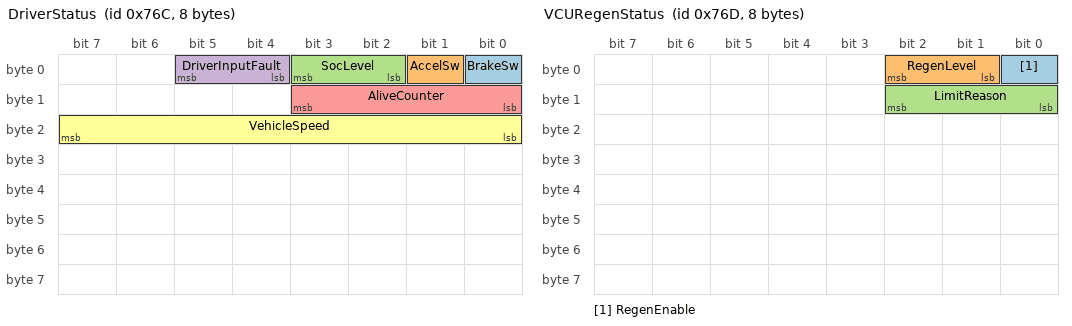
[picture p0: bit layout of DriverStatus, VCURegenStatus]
VERSION ""

NS_ :

BS_:

BU_: TestClient ECU4 ECU3 ECU1 ECU2

 BO_ 1900 DriverStatus: 8 TestClient
 SG_ BrakeSw : 0|1@1+ (1,0) [0|1] "" TestClient
 SG_ AccelSw : 1|1@1+ (1,0) [0|1] "" TestClient
 SG_ SocLevel : 2|2@1+ (1,0) [0|3] "" TestClient
 SG_ DriverInputFault : 4|2@1+ (1,0) [0|3] "" TestClient
 SG_ AliveCounter : 8|4@1+ (1,0) [0|15] "" TestClient
 SG_ VehicleSpeed : 16|8@1+ (1,0) [0|255] "km/h" TestClient

BO_ 1901 VCURegenStatus: 8 TestClient
 SG_ RegenEnable : 0|1@1+ (1,0) [0|1] "" TestClient
 SG_ RegenLevel : 1|2@1+ (1,0) [0|3] "" TestClient
 SG_ LimitReason : 8|3@1+ (1,0) [0|7] "" TestClient

 VAL_ 1900 BrakeSw 0 "OFF" 1 "ON";
VAL_ 1900 AccelSw 0 "OFF" 1 "ON";

0 "LOW"
1 "MID"
2 "HIGH"
3 "FULL";

0 "NONE"
1 "PEDAL_CONFLICT"
2 "INPUT_READ_FAIL"
3 "RESERVED";

0 "DISABLE"
1 "ENABLE";

0 "NONE"
1 "LOW"
2 "MID"
3 "HIGH";

0 "NONE"
1 "LOW_SPEED"
2 "SOC_FULL"
3 "FAULT"
4 "TIMEOUT";

BA_ "GenMsgCycleTime" BO_ 1900 10;
BA_ "GenMsgCycleTime" BO_ 1901 10;

BA_ "GenMsgSendType" BO_ 1900 0;
BA_ "GenMsgSendType" BO_ 1901 0;

BA_ "GenMsgDelayTime" BO_ 1900 0;
BA_ "GenMsgDelayTime" BO_ 1901 0;

BO_ 1799 GST_Msg_TP2: 8 TestClient
 SG_ GST_Msg_TP2_Sig1 : 0|64@1+ (1,0) [0|0] ""  ECU1

BO_ 1798 GST_Msg_TP1: 8 TestClient
 SG_ GST_Msg_TP1_Sig1 : 0|64@1+ (1,0) [0|0] ""  ECU1

BO_ 1797 ECU1_GST_Msg_TP: 8 ECU1
 SG_ ECU1_GST_TP_Sig1 : 7|64@0+ (1,0) [0|0] ""  TestClient

BO_ 85 ECU1_Msg_GW1: 8 ECU1
 SG_ ECU1_Msg_GW1_Sig2 : 15|8@0+ (1,0) [0|0] "" Vector__XXX
 SG_ ECU1_Msg_GW1_Sig1 : 7|8@0+ (1,0) [0|0] "" Vector__XXX

BO_ 1795 GST_Msg_TP_Phys: 8 TestClient
 SG_ GST_TP_Phys_Sig1 : 7|64@0+ (1,0) [0|0] ""  ECU1

BO_ 1796 ECU1_Msg_TP2: 8 ECU1
 SG_ ECU1_Msg_TP2_Sig1 : 0|64@1+ (1,0) [0|0] ""  TestClient

BO_ 769 ECU2_Msg_PIF1: 8 ECU2
 SG_ ECU2_Msg_PIF1_Sig2 : 31|8@0+ (1,0) [0|0] ""  ECU1
 SG_ ECU2_Msg_PIF1_Sig1 : 23|8@0+ (1,0) [0|0] ""  ECU1

BO_ 259 ECU2_Msg_POE1: 8 ECU2
 SG_ ECU2_Msg_POE1_Sig1 : 31|8@0+ (1,0) [0|0] ""  ECU1
 SG_ ECU2_Msg_POE1_Sig2 : 23|8@0+ (1,0) [0|0] ""  ECU1

BO_ 512 ECU1_Msg_IF1: 8 ECU1
 SG_ ECU1_Msg_IF1_Sig2 : 15|8@0+ (1,0) [0|0] ""  TestClient
 SG_ ECU1_Msg_IF1_Sig1 : 7|8@0+ (1,0) [0|0] ""  TestClient

BO_ 0 ECU2_Msg_OE2: 8 ECU2
 SG_ ECU2_Msg_OE2_Sig1 : 7|64@0+ (1,0) [0|0] ""  ECU3

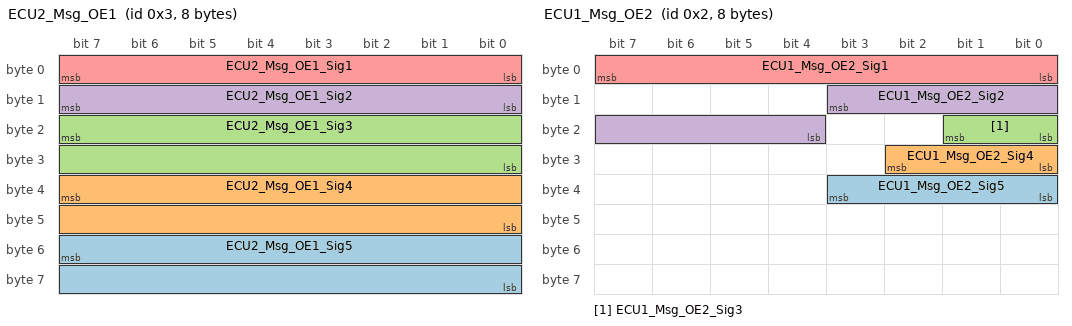
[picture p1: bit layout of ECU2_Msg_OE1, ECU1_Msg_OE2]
BO_ 3 ECU2_Msg_OE1: 8 ECU2
 SG_ ECU2_Msg_OE1_Sig5 : 55|16@0+ (1,0) [0|0] "" Vector__XXX
 SG_ ECU2_Msg_OE1_Sig4 : 39|16@0+ (1,0) [0|0] "" Vector__XXX
 SG_ ECU2_Msg_OE1_Sig3 : 23|16@0+ (1,0) [0|0] "" Vector__XXX
 SG_ ECU2_Msg_OE1_Sig2 : 15|8@0+ (1,0) [0|0] ""  ECU1
 SG_ ECU2_Msg_OE1_Sig1 : 7|8@0+ (1,0) [0|0] ""  ECU1

BO_ 1283 ECU2_Msg_P1: 2 ECU2
 SG_ ECU2_Msg_P1_Sig2 : 15|8@0+ (1,0) [0|0] ""  ECU1
 SG_ ECU2_Msg_P1_Sig1 : 7|8@0+ (1,0) [0|0] ""  ECU1

BO_ 256 ECU1_Msg_POE3: 8 ECU1
 SG_ ECU1_Msg_POE3_Sig2 : 15|8@0+ (1,0) [0|0] ""  ECU2
 SG_ ECU1_Msg_POE3_Sig1 : 7|8@0+ (1,0) [0|255] ""  ECU2

BO_ 2015 GST_Msg_TP_Func: 8 TestClient
 SG_ GST_TP_Func_Sig1 : 7|64@0+ (1,0) [0|0] ""  ECU1

BO_ 1793 ECU1_Msg_TP1: 8 ECU1
 SG_ ECU1_Msg_TP1_Sig1 : 0|64@1+ (1,0) [0|0] ""  TestClient

BO_ 1538 ECU1_Msg_P4: 8 ECU1
 SG_ ECU1_Msg_P4_Sig2 : 15|8@0+ (1,0) [0|0] ""  ECU2
 SG_ ECU1_Msg_P4_Sig1 : 7|8@0+ (1,0) [0|0] ""  ECU2

BO_ 1537 ECU1_Msg_P3: 8 ECU1
 SG_ ECU1_Msg_P3_Sig2 : 15|8@0+ (1,0) [0|0] ""  ECU2
 SG_ ECU1_Msg_P3_Sig1 : 7|8@0+ (1,0) [0|0] ""  ECU2

BO_ 768 ECU1_Msg_PIF1: 8 ECU1
 SG_ ECU1_Msg_PIF1_Sig2 : 15|8@0+ (1,0) [0|0] ""  TestClient
 SG_ ECU1_Msg_PIF1_Sig1 : 7|8@0+ (1,0) [0|0] ""  TestClient

BO_ 1282 ECU1_Msg_P2: 8 ECU1
 SG_ ECU1_Msg_P2_Sig2 : 15|8@0+ (1,0) [0|0] ""  ECU2
 SG_ ECU1_Msg_P2_Sig1 : 7|8@0+ (1,0) [0|0] ""  ECU2

BO_ 1281 ECU1_Msg_P1: 8 ECU1
 SG_ ECU1_Msg_P1_Sig2 : 15|8@0+ (1,0) [0|0] ""  ECU2
 SG_ ECU1_Msg_P1_Sig1 : 7|8@0+ (1,0) [0|0] ""  ECU2

BO_ 1028 ECU4_Msg_NM: 8 ECU4
 SG_ ECU4_Msg_NM_Sig1 : 7|8@0+ (1,0) [0|0] ""  ECU1,ECU2,ECU3

BO_ 1027 ECU3_Msg_NM: 8 ECU3
 SG_ ECU3_Msg_NM_Sig1 : 7|8@0+ (1,0) [0|0] ""  ECU1,ECU2,ECU4

BO_ 1026 ECU2_Msg_NM: 8 ECU2
 SG_ ECU2_Msg_NM_Sig1 : 7|8@0+ (1,0) [0|0] ""  ECU1,ECU3,ECU4

BO_ 1025 ECU1_Msg_NM: 8 ECU1
 SG_ ECU1_Msg_NM_Sig1 : 7|8@0+ (1,0) [0|0] ""  ECU2,ECU3,ECU4

BO_ 258 ECU1_Msg_POE2: 8 ECU1
 SG_ ECU1_Msg_POE2_Sig2 : 15|8@0+ (1,0) [0|0] ""  ECU2
 SG_ ECU1_Msg_POE2_Sig1 : 7|8@0+ (1,0) [0|0] ""  ECU2

BO_ 257 ECU1_Msg_POE1: 8 ECU1
 SG_ ECU1_Msg_POE1_Sig2 : 15|8@0+ (1,0) [0|0] ""  ECU2
 SG_ ECU1_Msg_POE1_Sig1 : 7|8@0+ (1,0) [0|0] ""  ECU2

BO_ 2 ECU1_Msg_OE2: 8 ECU1
 SG_ ECU1_Msg_OE2_Sig5 : 35|4@0+ (1,0) [0|15] "" Vector__XXX
 SG_ ECU1_Msg_OE2_Sig4 : 26|3@0+ (1,0) [0|7] "" Vector__XXX
 SG_ ECU1_Msg_OE2_Sig3 : 17|2@0+ (1,0) [0|3] "" Vector__XXX
 SG_ ECU1_Msg_OE2_Sig2 : 11|8@0+ (1,0) [0|0] ""  ECU2
 SG_ ECU1_Msg_OE2_Sig1 : 7|8@0+ (1,0) [0|0] ""  ECU2

BO_ 1 ECU1_Msg_OE1: 8 ECU1
 SG_ ECU1_Msg_OE1_Sig2 : 12|8@1+ (1,0) [0|0] ""  ECU2
 SG_ ECU1_Msg_OE1_Sig1 : 7|8@0+ (1,0) [0|0] ""  ECU2

EV_ ET_NwStartupTime: 0 [0|65535] "" 0 1 DUMMY_NODE_VECTOR3 Vector__XXX;

EV_ ET_ECU2_ILControlStop: 0 [0|0] "" 0 2 DUMMY_NODE_VECTOR3 Vector__XXX;

EV_ ET_ECU4_SilentNm: 0 [0|0] "" 0 3 DUMMY_NODE_VECTOR3 Vector__XXX;

EV_ ET_ECU3_SilentNm: 0 [0|0] "" 0 4 DUMMY_NODE_VECTOR3 Vector__XXX;

EV_ ET_ECU2_SilentNm: 0 [0|0] "" 0 5 DUMMY_NODE_VECTOR3 Vector__XXX;

EV_ ET_ECU4_SleepInd: 0 [0|0] "" 0 6 DUMMY_NODE_VECTOR3 Vector__XXX;

EV_ ET_ECU3_SleepInd: 0 [0|0] "" 0 7 DUMMY_NODE_VECTOR3 Vector__XXX;

EV_ ET_ECU2_SleepInd: 0 [0|0] "" 0 8 DUMMY_NODE_VECTOR3 Vector__XXX;

BA_DEF_ SG_  "GwSigLatencyTime" INT 0 65535;
BA_DEF_ SG_  "GwSigMissingSourceType" ENUM  "Undef","OldValue","DefaultValue","InitialValue";
BA_DEF_ SG_  "SignalCategory" HEX 10 15;
BA_DEF_ SG_  "GenSigEnvVarType" ENUM  "int","float","undef";
BA_DEF_ SG_  "GenSigSendType" ENUM  "Cyclic","OnWrite","OnWriteWithRepetition","OnChange","OnChangeWithRepetition","IfActive","IfActiveWithRepetition","NoSigSendType";
BA_DEF_ SG_  "GenSigInactiveValue" INT 0 65535;
BA_DEF_ BO_  "NmMessage" ENUM  "No","Yes";
BA_DEF_ BO_  "GenMsgILSupport" ENUM  "No","Yes";
BA_DEF_ BO_  "GenMsgSendType" ENUM  "Cyclic","not_used","not_used","not_used","not_used","not_used","not_used","not_used","NoMsgSendType";
BA_DEF_ BO_  "GenMsgNrOfRepetition" INT 0 3;
BA_DEF_ BO_  "GenMsgDelayTime" INT 0 20;
BA_DEF_ BO_  "GenMsgCycleTime" INT 0 2000;
BA_DEF_ BO_  "GenMsgCycleTimeFast" INT 0 500;
BA_DEF_ BU_  "NodeLayerModules" STRING ;
BA_DEF_ BU_  "GenNodSleepTime" INT 1375 1650;
BA_DEF_ BU_  "NmNode" ENUM  "No","Yes";
BA_DEF_ BU_  "NmStationAddress" HEX 0 255;
BA_DEF_ BU_  "NmCAN" INT 1 2;
BA_DEF_ BU_  "ILUsed" ENUM  "No","Yes";
BA_DEF_  "VersionWeek" INT 1 53;
BA_DEF_  "VersionMonth" INT 1 12;
BA_DEF_  "VersionDay" INT 1 31;
BA_DEF_  "BusType" STRING ;
BA_DEF_  "GenNWMTalkNM" STRING ;
BA_DEF_  "GenNWMSleepTime" INT 1375 1650;
BA_DEF_  "GenNWMGotoMode_BusSleep" STRING ;
BA_DEF_  "GenNWMGotoMode_Awake" STRING ;
BA_DEF_  "GenNWMApCanWakeUp" STRING ;
BA_DEF_  "GenNWMApCanSleep" STRING ;
BA_DEF_  "GenNWMApCanOn" STRING ;
BA_DEF_  "GenNWMApCanOff" STRING ;
BA_DEF_  "GenNWMApCanNormal" STRING ;
BA_DEF_  "GenNWMApBusSleep" STRING ;
BA_DEF_  "GenEnvVarPrefix" STRING ;
BA_DEF_  "GenEnvVarEndingSnd" STRING ;
BA_DEF_  "GenEnvVarEndingDsp" STRING ;
BA_DEF_  "NmType" STRING ;
BA_DEF_  "NmBaseAddress" HEX 0 2047;
BA_DEF_  "NmMessageCount" INT 0 128;
BA_DEF_  "Manufacturer" STRING ;
BA_DEF_  "Baudrate" INT 50000 500000;
BA_DEF_  "SamplePointMin" INT 55 85;
BA_DEF_  "SamplePointMax" INT 50 85;
BA_DEF_  "SyncJumpWidthMin" INT 1 4;
BA_DEF_  "SyncJumpWidthMax" INT 1 8;
BA_DEF_REL_ BU_SG_REL_  "GenSigTimeoutTime" INT 175 3500;
BA_DEF_DEF_  "GwSigLatencyTime" 40;
BA_DEF_DEF_  "GwSigMissingSourceType" "Undef";
BA_DEF_DEF_  "SignalCategory" 12;
BA_DEF_DEF_  "GenSigEnvVarType" "undef";
BA_DEF_DEF_  "GenSigSendType" "NoSigSendType";
BA_DEF_DEF_  "GenSigInactiveValue" 0;
BA_DEF_DEF_  "NmMessage" "No";
BA_DEF_DEF_  "GenMsgILSupport" "Yes";
BA_DEF_DEF_  "GenMsgSendType" "NoMsgSendType";
BA_DEF_DEF_  "GenMsgNrOfRepetition" 3;
BA_DEF_DEF_  "GenMsgDelayTime" 20;
BA_DEF_DEF_  "GenMsgCycleTime" 200;
BA_DEF_DEF_  "GenMsgCycleTimeFast" 40;
BA_DEF_DEF_  "NodeLayerModules" "oseknm01.dll";
BA_DEF_DEF_  "GenNodSleepTime" 1500;
BA_DEF_DEF_  "NmNode" "Yes";
BA_DEF_DEF_  "NmStationAddress" 0;
BA_DEF_DEF_  "NmCAN" 1;
BA_DEF_DEF_  "ILUsed" "Yes";
BA_DEF_DEF_  "VersionWeek" 1;
BA_DEF_DEF_  "VersionMonth" 1;
BA_DEF_DEF_  "VersionDay" 1;
BA_DEF_DEF_  "BusType" "CAN";
BA_DEF_DEF_  "GenNWMTalkNM" "TalkNM()";
BA_DEF_DEF_  "GenNWMSleepTime" 1500;
BA_DEF_DEF_  "GenNWMGotoMode_BusSleep" "GotoMode_BusSleep()";
BA_DEF_DEF_  "GenNWMGotoMode_Awake" "GotoMode_Awake()";
BA_DEF_DEF_  "GenNWMApCanWakeUp" "ApplCanWakeUp()";
BA_DEF_DEF_  "GenNWMApCanSleep" "ApplNmCanSleep()";
BA_DEF_DEF_  "GenNWMApCanOn" "ApplCanOnline()";
BA_DEF_DEF_  "GenNWMApCanOff" "ApplCanOffline()";
BA_DEF_DEF_  "GenNWMApCanNormal" "ApplNmCanNormal()";
BA_DEF_DEF_  "GenNWMApBusSleep" "ApplNmCanBusSleep()";
BA_DEF_DEF_  "GenEnvVarPrefix" "Env";
BA_DEF_DEF_  "GenEnvVarEndingSnd" "_";
BA_DEF_DEF_  "GenEnvVarEndingDsp" "Dsp_";
BA_DEF_DEF_  "NmType" "Vector";
BA_DEF_DEF_  "NmBaseAddress" 1024;
BA_DEF_DEF_  "NmMessageCount" 128;
BA_DEF_DEF_  "Manufacturer" "HMC";
BA_DEF_DEF_  "Baudrate" 100000;
BA_DEF_DEF_  "SamplePointMin" 75;
BA_DEF_DEF_  "SamplePointMax" 82;
BA_DEF_DEF_  "SyncJumpWidthMin" 2;
BA_DEF_DEF_  "SyncJumpWidthMax" 3;
BA_DEF_DEF_REL_ "GenSigTimeoutTime" 700;
BA_ "Baudrate" 500000;
BA_ "NmStationAddress" BU_ ECU4 4;
BA_ "NmStationAddress" BU_ ECU3 3;
BA_ "NmStationAddress" BU_ ECU1 1;
BA_ "NmStationAddress" BU_ ECU2 2;
BA_ "GenMsgILSupport" BO_ 1799 0;
BA_ "GenMsgNrOfRepetition" BO_ 1799 0;
BA_ "GenMsgDelayTime" BO_ 1799 0;
BA_ "GenMsgCycleTime" BO_ 1799 0;
BA_ "GenMsgCycleTimeFast" BO_ 1799 0;
BA_ "GenMsgILSupport" BO_ 1798 0;
BA_ "GenMsgNrOfRepetition" BO_ 1798 0;
BA_ "GenMsgDelayTime" BO_ 1798 0;
BA_ "GenMsgCycleTime" BO_ 1798 0;
BA_ "GenMsgCycleTimeFast" BO_ 1798 0;
BA_ "GenMsgCycleTimeFast" BO_ 1797 0;
BA_ "GenMsgCycleTime" BO_ 1797 0;
BA_ "GenMsgDelayTime" BO_ 1797 0;
BA_ "GenMsgNrOfRepetition" BO_ 1797 0;
BA_ "GenMsgILSupport" BO_ 1797 0;
BA_ "GenMsgILSupport" BO_ 1795 0;
BA_ "GenMsgNrOfRepetition" BO_ 1795 0;
BA_ "GenMsgDelayTime" BO_ 1795 0;
BA_ "GenMsgCycleTime" BO_ 1795 0;
BA_ "GenMsgCycleTimeFast" BO_ 1795 0;
BA_ "GenMsgILSupport" BO_ 1796 0;
BA_ "GenMsgNrOfRepetition" BO_ 1796 0;
BA_ "GenMsgDelayTime" BO_ 1796 0;
BA_ "GenMsgCycleTime" BO_ 1796 0;
BA_ "GenMsgCycleTimeFast" BO_ 1796 0;
BA_ "GenMsgCycleTimeFast" BO_ 769 200;
BA_ "GenMsgCycleTime" BO_ 769 500;
BA_ "GenMsgSendType" BO_ 769 0;
BA_ "GenMsgCycleTime" BO_ 259 500;
BA_ "GenMsgSendType" BO_ 259 0;
BA_ "GenMsgCycleTimeFast" BO_ 512 200;
BA_ "GenMsgCycleTime" BO_ 512 0;
BA_ "GenMsgCycleTime" BO_ 1283 500;
BA_ "GenMsgSendType" BO_ 1283 0;
BA_ "GenMsgNrOfRepetition" BO_ 1283 0;
BA_ "GenMsgCycleTimeFast" BO_ 1283 0;
BA_ "GenMsgSendType" BO_ 256 0;
BA_ "GenMsgCycleTimeFast" BO_ 2015 0;
BA_ "GenMsgCycleTime" BO_ 2015 0;
BA_ "GenMsgDelayTime" BO_ 2015 0;
BA_ "GenMsgNrOfRepetition" BO_ 2015 0;
BA_ "GenMsgILSupport" BO_ 2015 0;
BA_ "GenMsgCycleTimeFast" BO_ 1793 0;
BA_ "GenMsgCycleTime" BO_ 1793 0;
BA_ "GenMsgDelayTime" BO_ 1793 0;
BA_ "GenMsgNrOfRepetition" BO_ 1793 0;
BA_ "GenMsgILSupport" BO_ 1793 0;
BA_ "GenMsgCycleTimeFast" BO_ 1538 0;
BA_ "GenMsgNrOfRepetition" BO_ 1538 0;
BA_ "GenMsgSendType" BO_ 1538 0;
BA_ "GenMsgCycleTimeFast" BO_ 1537 0;
BA_ "GenMsgNrOfRepetition" BO_ 1537 0;
BA_ "GenMsgSendType" BO_ 1537 0;
BA_ "GenMsgSendType" BO_ 768 0;
BA_ "GenMsgCycleTimeFast" BO_ 768 200;
BA_ "GenMsgCycleTime" BO_ 768 500;
BA_ "GenMsgCycleTimeFast" BO_ 1282 0;
BA_ "GenMsgNrOfRepetition" BO_ 1282 0;
BA_ "GenMsgSendType" BO_ 1282 0;
BA_ "GenMsgCycleTime" BO_ 1281 500;
BA_ "GenMsgNrOfRepetition" BO_ 1281 0;
BA_ "GenMsgCycleTimeFast" BO_ 1281 0;
BA_ "GenMsgSendType" BO_ 1281 0;
BA_ "GenMsgCycleTimeFast" BO_ 1028 0;
BA_ "GenMsgCycleTime" BO_ 1028 0;
BA_ "GenMsgDelayTime" BO_ 1028 0;
BA_ "GenMsgNrOfRepetition" BO_ 1028 0;
BA_ "GenMsgILSupport" BO_ 1028 0;
BA_ "NmMessage" BO_ 1028 1;
BA_ "GenMsgCycleTimeFast" BO_ 1027 0;
BA_ "GenMsgCycleTime" BO_ 1027 0;
BA_ "GenMsgDelayTime" BO_ 1027 0;
BA_ "GenMsgNrOfRepetition" BO_ 1027 0;
BA_ "GenMsgILSupport" BO_ 1027 0;
BA_ "NmMessage" BO_ 1027 1;
BA_ "GenMsgCycleTimeFast" BO_ 1026 0;
BA_ "GenMsgCycleTime" BO_ 1026 0;
BA_ "GenMsgDelayTime" BO_ 1026 0;
BA_ "GenMsgNrOfRepetition" BO_ 1026 0;
BA_ "GenMsgILSupport" BO_ 1026 0;
BA_ "NmMessage" BO_ 1026 1;
BA_ "GenMsgCycleTimeFast" BO_ 1025 0;
BA_ "GenMsgCycleTime" BO_ 1025 0;
BA_ "GenMsgDelayTime" BO_ 1025 0;
BA_ "GenMsgNrOfRepetition" BO_ 1025 0;
BA_ "GenMsgILSupport" BO_ 1025 0;
BA_ "NmMessage" BO_ 1025 1;
BA_ "GenMsgSendType" BO_ 258 0;
BA_ "GenMsgSendType" BO_ 257 0;
BA_ "GenMsgCycleTime" BO_ 2 0;
BA_ "GenMsgCycleTime" BO_ 1 0;
BA_ "GenSigSendType" SG_ 1799 GST_Msg_TP2_Sig1 1;
BA_ "GenSigSendType" SG_ 1798 GST_Msg_TP1_Sig1 1;
BA_ "GenSigSendType" SG_ 1797 ECU1_GST_TP_Sig1 1;
BA_ "GenSigSendType" SG_ 85 ECU1_Msg_GW1_Sig2 2;
BA_ "GenSigSendType" SG_ 85 ECU1_Msg_GW1_Sig1 2;
BA_ "GenSigSendType" SG_ 1795 GST_TP_Phys_Sig1 1;
BA_ "GenSigSendType" SG_ 1796 ECU1_Msg_TP2_Sig1 1;
BA_ "GenSigInactiveValue" SG_ 769 ECU2_Msg_PIF1_Sig2 10;
BA_ "GenSigSendType" SG_ 769 ECU2_Msg_PIF1_Sig2 6;
BA_ "GenSigInactiveValue" SG_ 769 ECU2_Msg_PIF1_Sig1 20;
BA_ "GenSigSendType" SG_ 769 ECU2_Msg_PIF1_Sig1 6;
BA_ "GenSigSendType" SG_ 259 ECU2_Msg_POE1_Sig1 2;
BA_ "GenSigSendType" SG_ 259 ECU2_Msg_POE1_Sig2 4;
BA_ "GenSigInactiveValue" SG_ 512 ECU1_Msg_IF1_Sig2 10;
BA_ "GenSigSendType" SG_ 512 ECU1_Msg_IF1_Sig2 6;
BA_ "GenSigInactiveValue" SG_ 512 ECU1_Msg_IF1_Sig1 20;
BA_ "GenSigSendType" SG_ 512 ECU1_Msg_IF1_Sig1 6;
BA_ "GenSigSendType" SG_ 0 ECU2_Msg_OE2_Sig1 1;
BA_ "GenSigSendType" SG_ 3 ECU2_Msg_OE1_Sig5 1;
BA_ "GenSigSendType" SG_ 3 ECU2_Msg_OE1_Sig4 1;
BA_ "GenSigSendType" SG_ 3 ECU2_Msg_OE1_Sig3 1;
BA_ "GenSigSendType" SG_ 3 ECU2_Msg_OE1_Sig2 1;
BA_ "GenSigSendType" SG_ 3 ECU2_Msg_OE1_Sig1 1;
BA_ "GenSigSendType" SG_ 256 ECU1_Msg_POE3_Sig2 3;
BA_ "GenSigSendType" SG_ 256 ECU1_Msg_POE3_Sig1 1;
BA_ "GenSigSendType" SG_ 2015 GST_TP_Func_Sig1 1;
BA_ "GenSigSendType" SG_ 1793 ECU1_Msg_TP1_Sig1 1;
BA_ "GenSigInactiveValue" SG_ 768 ECU1_Msg_PIF1_Sig2 10;
BA_ "GenSigSendType" SG_ 768 ECU1_Msg_PIF1_Sig2 6;
BA_ "GenSigInactiveValue" SG_ 768 ECU1_Msg_PIF1_Sig1 20;
BA_ "GenSigSendType" SG_ 768 ECU1_Msg_PIF1_Sig1 6;
BA_ "GenSigSendType" SG_ 258 ECU1_Msg_POE2_Sig2 4;
BA_ "GenSigSendType" SG_ 258 ECU1_Msg_POE2_Sig1 2;
BA_ "GenSigSendType" SG_ 257 ECU1_Msg_POE1_Sig2 3;
BA_ "GenSigSendType" SG_ 257 ECU1_Msg_POE1_Sig1 1;
BA_ "GenSigSendType" SG_ 2 ECU1_Msg_OE2_Sig5 4;
BA_ "GenSigSendType" SG_ 2 ECU1_Msg_OE2_Sig4 4;
BA_ "GenSigSendType" SG_ 2 ECU1_Msg_OE2_Sig3 4;
BA_ "GenSigSendType" SG_ 2 ECU1_Msg_OE2_Sig2 4;
BA_ "GenSigSendType" SG_ 2 ECU1_Msg_OE2_Sig1 2;
BA_ "GenSigSendType" SG_ 1 ECU1_Msg_OE1_Sig2 3;
BA_ "GenSigSendType" SG_ 1 ECU1_Msg_OE1_Sig1 1;
